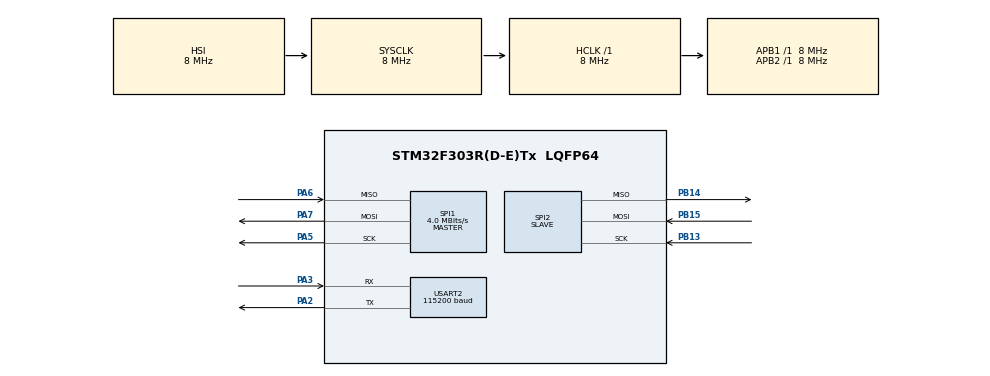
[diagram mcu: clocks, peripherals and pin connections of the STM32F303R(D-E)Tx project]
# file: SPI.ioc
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Mcu.Family=STM32F3
Mcu.Name=STM32F303R(D-E)Tx
Mcu.Package=LQFP64
NVIC.PriorityGroup=NVIC_PRIORITYGROUP_4
NVIC.SPI1_IRQn=true\:0\:0\:false\:false\:true\:true
NVIC.SPI2_IRQn=true\:0\:0\:false\:false\:true\:true
PA2.Mode=Asynchronous
PA2.Signal=USART2_TX
PA3.Mode=Asynchronous
PA3.Signal=USART2_RX
PA5.Mode=Full_Duplex_Master
PA5.Signal=SPI1_SCK
PA6.Mode=Full_Duplex_Master
PA6.Signal=SPI1_MISO
PA7.Mode=Full_Duplex_Master
PA7.Signal=SPI1_MOSI
PB13.Mode=Full_Duplex_Slave
PB13.Signal=SPI2_SCK
PB14.Mode=Full_Duplex_Slave
PB14.Signal=SPI2_MISO
PB15.Mode=Full_Duplex_Slave
PB15.Signal=SPI2_MOSI
PF0-OSC_IN.Mode=HSE-External-Oscillator
PF0-OSC_IN.Signal=RCC_OSC_IN
PF1-OSC_OUT.Mode=HSE-External-Oscillator
PF1-OSC_OUT.Signal=RCC_OSC_OUT
ProjectManager.HeapSize=0x200
ProjectManager.StackSize=0x400
ProjectManager.TargetToolchain=TrueSTUDIO
RCC.AHBFreq_Value=8000000
RCC.APB1Freq_Value=8000000
RCC.APB2Freq_Value=8000000
RCC.CortexFreq_Value=8000000
RCC.HSE_VALUE=8000000
RCC.HSI_VALUE=8000000
RCC.LSE_VALUE=32768
RCC.SYSCLKFreq_VALUE=8000000
RCC.USBFreq_Value=16000000
SPI1.CalculateBaudRate=4.0 MBits/s
SPI1.DataSize=SPI_DATASIZE_8BIT
SPI1.Direction=SPI_DIRECTION_2LINES
SPI1.Mode=SPI_MODE_MASTER
SPI1.VirtualType=VM_MASTER
SPI2.DataSize=SPI_DATASIZE_8BIT
SPI2.Direction=SPI_DIRECTION_2LINES
SPI2.Mode=SPI_MODE_SLAVE
SPI2.VirtualType=VM_SLAVE
USART2.BaudRate=115200
USART2.VirtualMode-Asynchronous=VM_ASYNC
USART2.WordLength=WORDLENGTH_8B
board=SPI

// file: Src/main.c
/**
  ******************************************************************************
  * @file           : main.c
  * @brief          : Main program body
  ******************************************************************************
  ** This notice applies to any and all portions of this file
  * that are not between comment pairs USER CODE BEGIN and
  * USER CODE END. Other portions of this file, whether
  * inserted by the user or by software development tools
  * are owned by their respective copyright owners.
  *
  * COPYRIGHT(c) 2018 STMicroelectronics
  *
  * Redistribution and use in source and binary forms, with or without modification,
  * are permitted provided that the following conditions are met:
  *   1. Redistributions of source code must retain the above copyright notice,
  *      this list of conditions and the following disclaimer.
  *   2. Redistributions in binary form must reproduce the above copyright notice,
  *      this list of conditions and the following disclaimer in the documentation
  *      and/or other materials provided with the distribution.
  *   3. Neither the name of STMicroelectronics nor the names of its contributors
  *      may be used to endorse or promote products derived from this software
  *      without specific prior written permission.
  *
  * THIS SOFTWARE IS PROVIDED BY THE COPYRIGHT HOLDERS AND CONTRIBUTORS "AS IS"
  * AND ANY EXPRESS OR IMPLIED WARRANTIES, INCLUDING, BUT NOT LIMITED TO, THE
  * IMPLIED WARRANTIES OF MERCHANTABILITY AND FITNESS FOR A PARTICULAR PURPOSE ARE
  * DISCLAIMED. IN NO EVENT SHALL THE COPYRIGHT HOLDER OR CONTRIBUTORS BE LIABLE
  * FOR ANY DIRECT, INDIRECT, INCIDENTAL, SPECIAL, EXEMPLARY, OR CONSEQUENTIAL
  * DAMAGES (INCLUDING, BUT NOT LIMITED TO, PROCUREMENT OF SUBSTITUTE GOODS OR
  * SERVICES; LOSS OF USE, DATA, OR PROFITS; OR BUSINESS INTERRUPTION) HOWEVER
  * CAUSED AND ON ANY THEORY OF LIABILITY, WHETHER IN CONTRACT, STRICT LIABILITY,
  * OR TORT (INCLUDING NEGLIGENCE OR OTHERWISE) ARISING IN ANY WAY OUT OF THE USE
  * OF THIS SOFTWARE, EVEN IF ADVISED OF THE POSSIBILITY OF SUCH DAMAGE.
  *
  ******************************************************************************
  */
#include "main.h"
#include "stm32f3xx_hal.h"

SPI_HandleTypeDef hspi1;
SPI_HandleTypeDef hspi2;

UART_HandleTypeDef huart2;

/* USER CODE BEGIN PV */
/* Private variables ---------------------------------------------------------*/

/* USER CODE END PV */

void SystemClock_Config(void);
static void MX_GPIO_Init(void);
static void MX_SPI1_Init(void);
static void MX_SPI2_Init(void);
static void MX_USART2_UART_Init(void);

/* USER CODE BEGIN PFP */
/* Private function prototypes -----------------------------------------------*/

/* USER CODE END PFP */
char ms[50]="Msg from master: ";
char master_tx_buffer[50],master_rx_buffer[50];
char slave_tx_buffer[50]="Msg from slave: Msg get!\r\n\0",slave_rx_buffer[50];
int var=0;
/* USER CODE BEGIN 0 */

void HAL_SPI_TxRxCpltCallback(SPI_HandleTypeDef* hspi){
	if(hspi->Instance==SPI2){
		HAL_UART_Transmit(&huart2,slave_rx_buffer,strlen(slave_rx_buffer),500);
		HAL_SPI_TransmitReceive_IT(&hspi2,&slave_tx_buffer,&slave_rx_buffer,50);
	}
}

/* USER CODE END 0 */

int main(void)
{

  /* MCU Configuration----------------------------------------------------------*/

  /* Reset of all peripherals, Initializes the Flash interface and the Systick. */
  HAL_Init();

  /* Configure the system clock */
  SystemClock_Config();

  /* Initialize all configured peripherals */
  MX_GPIO_Init();
  MX_SPI1_Init();
  MX_SPI2_Init();
  MX_USART2_UART_Init();
  /* USER CODE BEGIN 2 */
  HAL_SPI_TransmitReceive_IT(&hspi2,&slave_tx_buffer,&slave_rx_buffer,50);
  /* USER CODE END 2 */

  /* Infinite loop */
  while (1)
  {
	  sprintf(master_tx_buffer,"%s %d\r\n\0",ms,var++);
	  HAL_SPI_TransmitReceive(&hspi1,&master_tx_buffer,&master_rx_buffer,50,500);
	  HAL_UART_Transmit(&huart2,master_rx_buffer,strlen(master_rx_buffer),500);
	  HAL_Delay(500);
  }

}

void SystemClock_Config(void)
{

  RCC_OscInitTypeDef RCC_OscInitStruct;
  RCC_ClkInitTypeDef RCC_ClkInitStruct;
  RCC_PeriphCLKInitTypeDef PeriphClkInit;

    /**Initializes the CPU, AHB and APB busses clocks
    */
  RCC_OscInitStruct.OscillatorType = RCC_OSCILLATORTYPE_HSI;
  RCC_OscInitStruct.HSIState = RCC_HSI_ON;
  RCC_OscInitStruct.HSICalibrationValue = 16;
  RCC_OscInitStruct.PLL.PLLState = RCC_PLL_NONE;
  if (HAL_RCC_OscConfig(&RCC_OscInitStruct) != HAL_OK)
  {
    _Error_Handler(__FILE__, __LINE__);
  }

    /**Initializes the CPU, AHB and APB busses clocks
    */
  RCC_ClkInitStruct.ClockType = RCC_CLOCKTYPE_HCLK|RCC_CLOCKTYPE_SYSCLK
                              |RCC_CLOCKTYPE_PCLK1|RCC_CLOCKTYPE_PCLK2;
  RCC_ClkInitStruct.SYSCLKSource = RCC_SYSCLKSOURCE_HSI;
  RCC_ClkInitStruct.AHBCLKDivider = RCC_SYSCLK_DIV1;
  RCC_ClkInitStruct.APB1CLKDivider = RCC_HCLK_DIV1;
  RCC_ClkInitStruct.APB2CLKDivider = RCC_HCLK_DIV1;

  if (HAL_RCC_ClockConfig(&RCC_ClkInitStruct, FLASH_LATENCY_0) != HAL_OK)
  {
    _Error_Handler(__FILE__, __LINE__);
  }

  PeriphClkInit.PeriphClockSelection = RCC_PERIPHCLK_USART2;
  PeriphClkInit.Usart2ClockSelection = RCC_USART2CLKSOURCE_PCLK1;
  if (HAL_RCCEx_PeriphCLKConfig(&PeriphClkInit) != HAL_OK)
  {
    _Error_Handler(__FILE__, __LINE__);
  }

    /**Configure the Systick interrupt time
    */
  HAL_SYSTICK_Config(HAL_RCC_GetHCLKFreq()/1000);

    /**Configure the Systick
    */
  HAL_SYSTICK_CLKSourceConfig(SYSTICK_CLKSOURCE_HCLK);

  /* SysTick_IRQn interrupt configuration */
  HAL_NVIC_SetPriority(SysTick_IRQn, 0, 0);
}

/* SPI1 init function */
static void MX_SPI1_Init(void)
{

  /* SPI1 parameter configuration*/
  hspi1.Instance = SPI1;
  hspi1.Init.Mode = SPI_MODE_MASTER;
  hspi1.Init.Direction = SPI_DIRECTION_2LINES;
  hspi1.Init.DataSize = SPI_DATASIZE_8BIT;
  hspi1.Init.CLKPolarity = SPI_POLARITY_LOW;
  hspi1.Init.CLKPhase = SPI_PHASE_1EDGE;
  hspi1.Init.NSS = SPI_NSS_SOFT;
  hspi1.Init.BaudRatePrescaler = SPI_BAUDRATEPRESCALER_2;
  hspi1.Init.FirstBit = SPI_FIRSTBIT_MSB;
  hspi1.Init.TIMode = SPI_TIMODE_DISABLE;
  hspi1.Init.CRCCalculation = SPI_CRCCALCULATION_DISABLE;
  hspi1.Init.CRCPolynomial = 7;
  hspi1.Init.CRCLength = SPI_CRC_LENGTH_DATASIZE;
  hspi1.Init.NSSPMode = SPI_NSS_PULSE_ENABLE;
  if (HAL_SPI_Init(&hspi1) != HAL_OK)
  {
    _Error_Handler(__FILE__, __LINE__);
  }

}

/* SPI2 init function */
static void MX_SPI2_Init(void)
{

  /* SPI2 parameter configuration*/
  hspi2.Instance = SPI2;
  hspi2.Init.Mode = SPI_MODE_SLAVE;
  hspi2.Init.Direction = SPI_DIRECTION_2LINES;
  hspi2.Init.DataSize = SPI_DATASIZE_8BIT;
  hspi2.Init.CLKPolarity = SPI_POLARITY_LOW;
  hspi2.Init.CLKPhase = SPI_PHASE_1EDGE;
  hspi2.Init.NSS = SPI_NSS_SOFT;
  hspi2.Init.FirstBit = SPI_FIRSTBIT_MSB;
  hspi2.Init.TIMode = SPI_TIMODE_DISABLE;
  hspi2.Init.CRCCalculation = SPI_CRCCALCULATION_DISABLE;
  hspi2.Init.CRCPolynomial = 7;
  hspi2.Init.CRCLength = SPI_CRC_LENGTH_DATASIZE;
  hspi2.Init.NSSPMode = SPI_NSS_PULSE_DISABLE;
  if (HAL_SPI_Init(&hspi2) != HAL_OK)
  {
    _Error_Handler(__FILE__, __LINE__);
  }

}

/* USART2 init function */
static void MX_USART2_UART_Init(void)
{

  huart2.Instance = USART2;
  huart2.Init.BaudRate = 115200;
  huart2.Init.WordLength = UART_WORDLENGTH_8B;
  huart2.Init.StopBits = UART_STOPBITS_1;
  huart2.Init.Parity = UART_PARITY_NONE;
  huart2.Init.Mode = UART_MODE_TX_RX;
  huart2.Init.HwFlowCtl = UART_HWCONTROL_NONE;
  huart2.Init.OverSampling = UART_OVERSAMPLING_16;
  huart2.Init.OneBitSampling = UART_ONE_BIT_SAMPLE_DISABLE;
  huart2.AdvancedInit.AdvFeatureInit = UART_ADVFEATURE_NO_INIT;
  if (HAL_UART_Init(&huart2) != HAL_OK)
  {
    _Error_Handler(__FILE__, __LINE__);
  }

}

/** Configure pins as
        * Analog
        * Input
        * Output
        * EVENT_OUT
        * EXTI
*/
static void MX_GPIO_Init(void)
{

  /* GPIO Ports Clock Enable */
  __HAL_RCC_GPIOF_CLK_ENABLE();
  __HAL_RCC_GPIOA_CLK_ENABLE();
  __HAL_RCC_GPIOB_CLK_ENABLE();

}

void _Error_Handler(char *file, int line)
{
  while(1)
  {
  }
}

/************************ (C) COPYRIGHT STMicroelectronics *****END OF FILE****/
